# MTB_1.0 register map
Vendor: Texas Instruments
Peripheral module from a debugger description file (folder msp).
Registers are 32-bit, read-only, no defined reset value unless marked. A register's access mark holds for its fields unless they carry their own. Offsets are as the file gives them; lines under a group give offsets from that group; [hi:lo] are bit positions; {n}, {i} and the like mark numbered series; 'fields as' and 'values as' point back to an identical list; <NAME> marks a mode.

## MTB
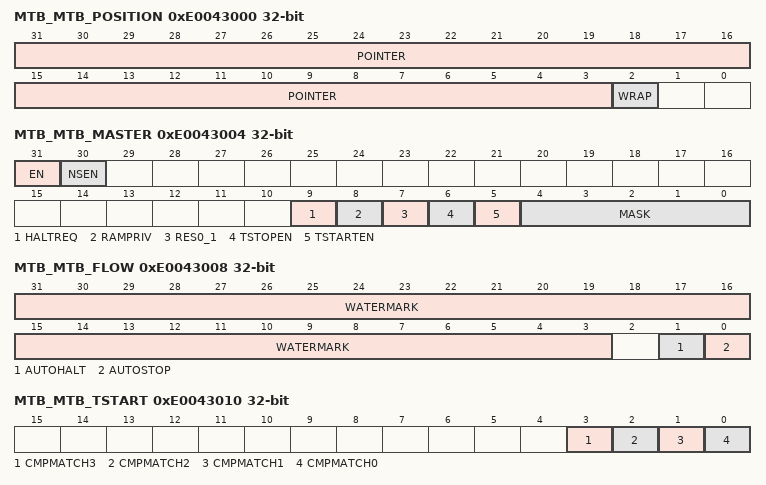
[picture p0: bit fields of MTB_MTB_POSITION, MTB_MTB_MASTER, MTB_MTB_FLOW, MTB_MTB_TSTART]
0xE0043000 MTB_MTB_POSITION access per field — The MTB_POSITION register contains the trace write pointer and the wrap bit.
  [31:3] POINTER rw, [2] WRAP rw
0xE0043004 MTB_MTB_MASTER access per field — The MTB_MASTER register contains the main trace enable bit and other trace control fields.
  [31] EN rw
  [30] NSEN rw
  [9] HALTREQ rw
  [8] RAMPRIV rw
  [7] RES0_1 ro — Reserved, RES0
  [6] TSTOPEN rw
  [5] TSTARTEN rw
  [4:0] MASK rw
0xE0043008 MTB_MTB_FLOW access per field — The MTB_FLOW register contains the WATERMARK address and the AUTOSTOP and AUTOHALT control bits.
  [31:3] WATERMARK rw, [1] AUTOHALT rw, [0] AUTOSTOP rw
0xE004300C MTB_MTB_BASE — The MTB_BASE register indicates where the SRAM is located in the processor memory map.
  [31:5] BASE
0xE0043010 MTB_MTB_TSTART access per field — The MTB_TSTART register controls the trace start events using the DWT CMPMATCH feature.
  [3] CMPMATCH3 ro — Reserved, `ImpDefRES0
  [2] CMPMATCH2 ro — Reserved, `ImpDefRES0
  [1] CMPMATCH1 rw
  [0] CMPMATCH0 rw
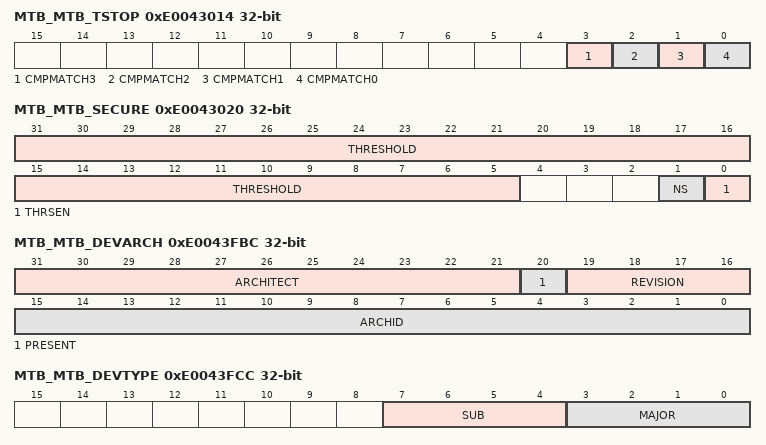
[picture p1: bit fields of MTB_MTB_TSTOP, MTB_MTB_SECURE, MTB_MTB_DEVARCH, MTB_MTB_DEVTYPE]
0xE0043014 MTB_MTB_TSTOP access per field — The MTB_TSTOP register controls the trace stop events using the DWT CMPMATCH feature.
  fields as MTB_MTB_TSTART
0xE0043020 MTB_MTB_SECURE access per field — The MTB_SECURE register allows the SRAM region to be partitioned into two regions, with one region being defined as Secure and the other as Non-secure.
  [31:5] THRESHOLD rw, [1] NS rw, [0] THRSEN rw
0xE0043FBC MTB_MTB_DEVARCH — MTB_DEVARCH
  [31:21] ARCHITECT — reads as 0x23B
  [20] PRESENT — reads as 0b1
  [19:16] REVISION — reads as 0x0
  [15:0] ARCHID — reads as 0x0A31
0xE0043FC8 MTB_MTB_DEVID access not given — MTB_DEVID
0xE0043FCC MTB_MTB_DEVTYPE — MTB_DEVTYPE
  [7:4] SUB — reads as 0x3
  [3:0] MAJOR — reads as 0x1
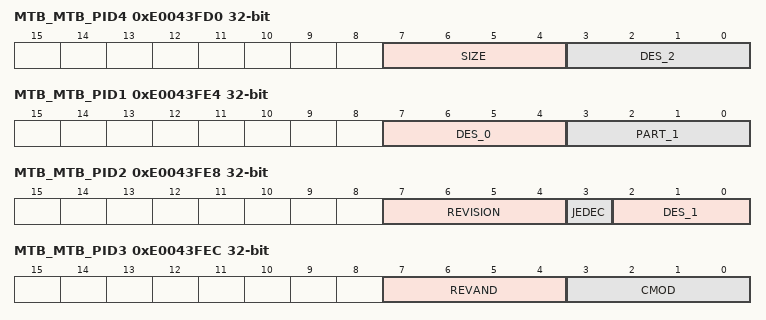
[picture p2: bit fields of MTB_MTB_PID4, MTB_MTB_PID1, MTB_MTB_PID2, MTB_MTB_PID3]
0xE0043FD0 MTB_MTB_PID4 — MTB_PID4
  [7:4] SIZE — reads as 0x0
  [3:0] DES_2 — reads as 0x4
{0xE0043FC0+4i} MTB_MTB_PID{i} access not given (i=5..7) — MTB_PID{i}
0xE0043FE0 MTB_MTB_PID0 — MTB_PID0
  [7:0] PART_0 — reads as 0x8E
0xE0043FE4 MTB_MTB_PID1 — MTB_PID1
  [7:4] DES_0 — reads as 0xB
  [3:0] PART_1 — reads as 0x9
0xE0043FE8 MTB_MTB_PID2 — MTB_PID2
  [7:4] REVISION — reads as 0x0
  [3] JEDEC — reads as 0b1
  [2:0] DES_1 — reads as 0b011
0xE0043FEC MTB_MTB_PID3 — MTB_PID3
  [7:4] REVAND — reads as 0x0
  [3:0] CMOD — reads as 0x0
0xE0043FF0 MTB_MTB_CID0 — MTB_CID0
  [7:0] PRMBL_0 — reads as 0x0D
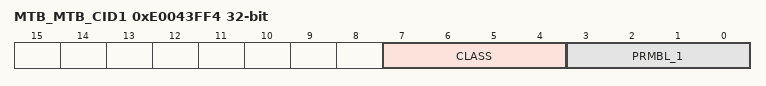
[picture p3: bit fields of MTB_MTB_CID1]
0xE0043FF4 MTB_MTB_CID1 — MTB_CID1
  [7:4] CLASS — reads as 0x9
  [3:0] PRMBL_1 — reads as 0x0
0xE0043FF8 MTB_MTB_CID2 — MTB_CID2
  [7:0] PRMBL_2 — reads as 0x05
0xE0043FFC MTB_MTB_CID3 — MTB_CID3
  [7:0] PRMBL_3 — reads as 0xB1
